# M051AN_v1 register map
File version: 1.0
Registers are 32-bit, read-write, reset 0x0 unless marked. A register's access mark holds for its fields unless they carry their own. Offsets are from the block's base; [hi:lo] are bit positions.

## EBI_CTL — EBI Register Map
Base 0x50010000
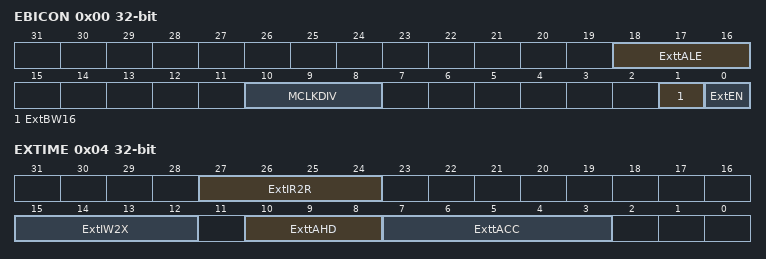
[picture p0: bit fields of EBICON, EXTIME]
0x00 EBICON — External Bus Interface General Control Register
  [18:16] ExttALE — Expand Time of ALE. The ALE width (tALE) to latch the address can be controlled by ExttALE.
  [10:8] MCLKDIV — External Output Clock Divider
  [1] ExtBW16 — EBI data width 16 bit. This bit defines if the data bus is 8-bit or 16-bit.
    0=EBI data width is 8 bit; 1=EBI data width is 16 bit
  [0] ExtEN — EBI Enable. This bit is the functional enable bit for EBI.
    0=EBI function is disabled; 1=EBI function is enabled
0x04 EXTIME — External Bus Interface Timing Control Register
  [27:24] ExtIR2R — Idle State Cycle Between Read-Read. When read action is finish and next action is going to read, idle state is inserted and nCS return to high if ExtIR2R is not zero.
  [15:12] ExtIW2X — Idle State Cycle After Write. When write action is finish, idle state is inserted and nCS return to high if ExtIW2X is not zero.
  [10:8] ExttAHD — EBI Data Access Hold Time. ExttAHD define data access hold time (tAHD).
  [7:3] ExttACC — EBI Data Access Time. ExttACC define data access time (tACC).

## FMC — FMC Register Map
Base 0x5000C000
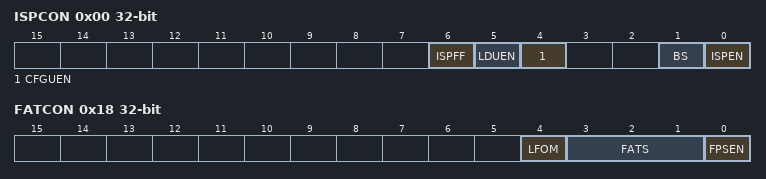
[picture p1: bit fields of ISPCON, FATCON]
0x00 ISPCON — ISP Control Register
  [6] ISPFF — ISP Fail Flag. This bit is set by hardware when a triggered ISP meets any of the following conditions: (1) APROM writes to itself. (2) LDROM writes to itself. (3) Destination address is illegal, such as over an available range. Note: Write 1 to clear this bit to zero.
  [5] LDUEN — LDROM Update Enable. LDROM update enable bit.
    0=LDROM cannot be updated; 1=LDROM can be updated when the MCU runs in APROM
  [4] CFGUEN — Config Update Enable. Writing this bit to 1 enables s/w to update Config value by ISP procedure regardless of program code is running in APROM or LDROM.
    0=Config update disable; 1=Config update enable
  [1] BS — Boot Select. This bit is protected bit. Set/clear this bit to select next booting from LDROM/APROM, respectively. This bit also functions as MCU booting status flag, which can be used to check where MCU booted from. This bit is initiated with the inversed value of CBS in Config0 after power-on reset; It keeps the same value at other reset.
    0=boot from APROM; 1=boot from LDROM
  [0] ISPEN — ISP Enable. This bit is protected bit. ISP function enable bit. Set this bit to enable ISP function.
    0=Disable ISP function; 1=Enable ISP function
0x04 ISPADR — ISP Address Register
  [31:0] ISPADR — ISP Address. NuMicro M051 series equips with a maximum 16kx32 embedded flash, it supports word program only. ISPADR[1:0] must be kept 00b for ISP operation.
0x08 ISPDAT — ISP Data Register
  [31:0] ISPDAT — ISP Data. Write data to this register before ISP program operation. Read data from this register after ISP read operation
0x0C ISPCMD — ISP Command Register
  [5:0] ISPCMD — ISP Command
0x10 ISPTRG — ISP Trigger Control Register
  [0] ISPGO — ISP start trigger. Write 1 to start ISP operation and this bit will be cleared to 0 by hardware automatically when ISP operation is finish.
    0=ISP done; 1=ISP is on going
0x14 DFBADR ro reset 0x1F000 — Data Flash Base Address
  [31:0] DFBADR — Data Flash Base Address. This register indicates data flash start address. It is a read only register. For 8/16/32/64KB flash memory device, the data flash size is 4KB and it start address is fixed at 0x0001_F000 by hardware internally.
0x18 FATCON — Flash Access Time Control Register
  [4] LFOM — Low Frequency Optimization Mode (write-protection bit). When chip operation frequency is lower than 25 MHz, chip can work more efficiently by setting this bit to 1
    0=Disable flash low frequency optimization mode; 1=Enable flash low frequency optimization mode
  [3:1] FATS — Flash Access Time Window Select
  [0] FPSEN — Flash Power Save Enable. If CPU clock is slower than 24 MHz, then s/w can enable flash power saving function
    0=Disable flash power saving; 1=Enable flash power saving
